# STM32H7RSxx register map
File version: 0.1
CPU: CM7 r0p1, little endian, MPU, FPU, 4 interrupt priority bits
Registers are 32-bit, read-write, reset 0x0 unless marked. A register's access mark holds for its fields unless they carry their own. Offsets are from the block's base; [hi:lo] are bit positions; lines under a group give offsets from that group; {n}, {i} and the like mark numbered series.

## ADC1 (part 1 of 2) — Analog to digital converter
Base 0x40022000
Same registers: ADC2 0x40022100
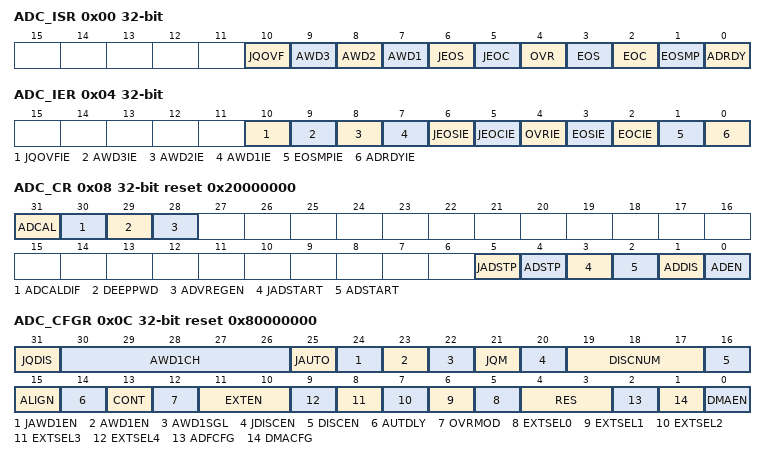
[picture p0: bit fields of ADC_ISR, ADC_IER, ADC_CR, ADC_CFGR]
0x00 ADC_ISR — ADC interrupt and status register
  [10] JQOVF — Injected context queue overflow This bit is set by hardware when an Overflow of the Injected Queue of Context occurs. It is cleared by software writing 1 to it. Refer to for more information.
    0=No injected context queue overflow occurred (or the flag event was already acknowledged and cleared by software); 1=Injected context queue overflow has occurred
  [9] AWD3 — Analog watchdog 3 flag This bit is set by hardware when the converted voltage crosses the values programmed in the fields LT3[7:0] and HT3[7:0] of ADC_TR3 register. It is cleared by software writing 1 to it.
    0=No analog watchdog 3 event occurred (or the flag event was already acknowledged and cleared by software); 1=Analog watchdog 3 event occurred
  [8] AWD2 — Analog watchdog 2 flag This bit is set by hardware when the converted voltage crosses the values programmed in the fields LT2[7:0] and HT2[7:0] of ADC_TR2 register. It is cleared by software writing 1 to it.
    0=No analog watchdog 2 event occurred (or the flag event was already acknowledged and cleared by software); 1=Analog watchdog 2 event occurred
  [7] AWD1 — Analog watchdog 1 flag This bit is set by hardware when the converted voltage crosses the values programmed in the fields LT1[11:0] and HT1[11:0] of ADC_TR1 register. It is cleared by software. writing 1 to it.
    0=No analog watchdog 1 event occurred (or the flag event was already acknowledged and cleared by software); 1=Analog watchdog 1 event occurred
  [6] JEOS — Injected channel end of sequence flag This bit is set by hardware at the end of the conversions of all injected channels in the group. It is cleared by software writing 1 to it.
    0=Injected conversion sequence not complete (or the flag event was already acknowledged and cleared by software); 1=Injected conversions complete
  [5] JEOC — Injected channel end of conversion flag This bit is set by hardware at the end of each injected conversion of a channel when a new data is available in the corresponding ADC_JDRy register. It is cleared by software writing 1 to it or by reading the corresponding ADC_JDRy register
    0=Injected channel conversion not complete (or the flag event was already acknowledged and cleared by software); 1=Injected channel conversion complete
  [4] OVR — ADC overrun This bit is set by hardware when an overrun occurs on a regular channel, meaning that a new conversion has completed while the EOC flag was already set. It is cleared by software writing 1 to it.
    0=No overrun occurred (or the flag event was already acknowledged and cleared by software); 1=Overrun has occurred
  [3] EOS — End of regular sequence flag This bit is set by hardware at the end of the conversions of a regular sequence of channels. It is cleared by software writing 1 to it.
    0=Regular Conversions sequence not complete (or the flag event was already acknowledged and cleared by software); 1=Regular Conversions sequence complete
  [2] EOC — End of conversion flag This bit is set by hardware at the end of each regular conversion of a channel when a new data is available in the ADC_DR register. It is cleared by software writing 1 to it or by reading the ADC_DR register
    0=Regular channel conversion not complete (or the flag event was already acknowledged and cleared by software); 1=Regular channel conversion complete
  [1] EOSMP — End of sampling flag This bit is set by hardware during the conversion of any channel (only for regular channels), at the end of the sampling phase.
    0=not at the end of the sampling phase (or the flag event was already acknowledged and cleared by software); 1=End of sampling phase reached
  [0] ADRDY — ADC ready This bit is set by hardware after the ADC has been enabled (ADEN = 1) and when the ADC reaches a state where it is ready to accept conversion requests. It is cleared by software writing 1 to it.
    0=ADC not yet ready to start conversion (or the flag event was already acknowledged and cleared by software); 1=ADC is ready to start conversion
0x04 ADC_IER — ADC interrupt enable register
  [10] JQOVFIE — Injected context queue overflow interrupt enable This bit is set and cleared by software to enable/disable the Injected Context Queue Overflow interrupt. Note: The software is allowed to write this bit only when JADSTART = 0 (which ensures that no injected conversion is ongoing).
    0=Injected Context Queue Overflow interrupt disabled; 1=Injected Context Queue Overflow interrupt enabled. An interrupt is generated when the JQOVF bit is set.
  [9] AWD3IE — Analog watchdog 3 interrupt enable This bit is set and cleared by software to enable/disable the analog watchdog 2 interrupt. Note: The software is allowed to write this bit only when ADSTART = 0 and JADSTART = 0 (which ensures that no conversion is ongoing).
    0=Analog watchdog 3 interrupt disabled; 1=Analog watchdog 3 interrupt enabled
  [8] AWD2IE — Analog watchdog 2 interrupt enable This bit is set and cleared by software to enable/disable the analog watchdog 2 interrupt. Note: The software is allowed to write this bit only when ADSTART = 0 and JADSTART = 0 (which ensures that no conversion is ongoing).
    0=Analog watchdog 2 interrupt disabled; 1=Analog watchdog 2 interrupt enabled
  [7] AWD1IE — Analog watchdog 1 interrupt enable This bit is set and cleared by software to enable/disable the analog watchdog 1 interrupt. Note: The software is allowed to write this bit only when ADSTART = 0 and JADSTART = 0 (which ensures that no conversion is ongoing).
    0=Analog watchdog 1 interrupt disabled; 1=Analog watchdog 1 interrupt enabled
  [6] JEOSIE — End of injected sequence of conversions interrupt enable This bit is set and cleared by software to enable/disable the end of injected sequence of conversions interrupt. Note: The software is allowed to write this bit only when JADSTART = 0 (which ensures that no injected conversion is ongoing).
    0=JEOS interrupt disabled; 1=JEOS interrupt enabled. An interrupt is generated when the JEOS bit is set.
  [5] JEOCIE — End of injected conversion interrupt enable This bit is set and cleared by software to enable/disable the end of an injected conversion interrupt. Note: The software is allowed to write this bit only when JADSTART = 0 (which ensures that no injected conversion is ongoing).
    0=JEOC interrupt disabled; 1=JEOC interrupt enabled. An interrupt is generated when the JEOC bit is set.
  [4] OVRIE — Overrun interrupt enable This bit is set and cleared by software to enable/disable the Overrun interrupt of a regular conversion. Note: The software is allowed to write this bit only when ADSTART = 0 (which ensures that no regular conversion is ongoing).
    0=Overrun interrupt disabled; 1=Overrun interrupt enabled. An interrupt is generated when the OVR bit is set.
  [3] EOSIE — End of regular sequence of conversions interrupt enable This bit is set and cleared by software to enable/disable the end of regular sequence of conversions interrupt. Note: The software is allowed to write this bit only when ADSTART = 0 (which ensures that no regular conversion is ongoing).
    0=EOS interrupt disabled; 1=EOS interrupt enabled. An interrupt is generated when the EOS bit is set.
  [2] EOCIE — End of regular conversion interrupt enable This bit is set and cleared by software to enable/disable the end of a regular conversion interrupt. Note: The software is allowed to write this bit only when ADSTART = 0 (which ensures that no regular conversion is ongoing).
    0=EOC interrupt disabled; 1=EOC interrupt enabled. An interrupt is generated when the EOC bit is set.
  [1] EOSMPIE — End of sampling flag interrupt enable for regular conversions This bit is set and cleared by software to enable/disable the end of the sampling phase interrupt for regular conversions. Note: The software is allowed to write this bit only when ADSTART = 0 (which ensures that no regular conversion is ongoing).
    0=EOSMP interrupt disabled; 1=EOSMP interrupt enabled. An interrupt is generated when the EOSMP bit is set.
  [0] ADRDYIE — ADC ready interrupt enable This bit is set and cleared by software to enable/disable the ADC Ready interrupt. Note: The software is allowed to write this bit only when ADSTART = 0 and JADSTART = 0 (which ensures that no conversion is ongoing).
    0=ADRDY interrupt disabled; 1=ADRDY interrupt enabled. An interrupt is generated when the ADRDY bit is set.
0x08 ADC_CR reset 0x20000000 — ADC control register
  [31] ADCAL — ADC calibration This bit is set by software to start the calibration of the ADC. Program first the bit ADCALDIF to determine if this calibration applies for Single-ended or Differential inputs mode. It is cleared by hardware after calibration is complete. Note: The software is allowed to launch a calibration by setting ADCAL only when ADEN = 0. The software is allowed to update the calibration factor by writing ADC_CALFACT only when ADEN = 1 and ADSTART = 0 and JADSTART = 0 (ADC enabled and no conversion is ongoing)
    0=Calibration complete; 1=Write 1 to calibrate the ADC. Read at 1 means that a calibration in progress.
  [30] ADCALDIF — Differential mode for calibration This bit is set and cleared by software to configure the Single-ended or Differential inputs mode for the calibration. Note: The software is allowed to write this bit only when the ADC is disabled and is not calibrating (ADCAL = 0, JADSTART = 0, JADSTP = 0, ADSTART = 0, ADSTP = 0, ADDIS = 0 and ADEN = 0).
    0=Writing ADCAL launches a calibration in Single-ended inputs mode; 1=Writing ADCAL launches a calibration in Differential inputs mode
  [29] DEEPPWD — Deep-power-down enable This bit is set and cleared by software to put the ADC in Deep-power-down mode. Note: The software is allowed to write this bit only when the ADC is disabled (ADCAL = 0, JADSTART = 0, JADSTP = 0, ADSTART = 0, ADSTP = 0, ADDIS = 0 and ADEN = 0).
    0=ADC not in Deep-power down; 1=ADC in Deep-power-down (default reset state)
  [28] ADVREGEN — ADC voltage regulator enable This bits is set by software to enable the ADC voltage regulator. Before performing any operation such as launching a calibration or enabling the ADC, the ADC voltage regulator must first be enabled and the software must wait for the regulator start-up time. For more details about the ADC voltage regulator enable and disable sequences, refer to (ADVREGEN). The software can program this bit field only when the ADC is disabled (ADCAL = 0, JADSTART = 0, ADSTART = 0, ADSTP = 0, ADDIS = 0 and ADEN = 0).
    0=ADC Voltage regulator disabled; 1=ADC Voltage regulator enabled
  [5] JADSTP — ADC stop of injected conversion command This bit is set by software to stop and discard an ongoing injected conversion (JADSTP Command). It is cleared by hardware when the conversion is effectively discarded and the ADC injected sequence and triggers can be re-configured. The ADC is then ready to accept a new start of injected conversions (JADSTART command). Note: The software is allowed to set JADSTP only when JADSTART = 1 and ADDIS = 0 (ADC is enabled and eventually converting an injected conversion and there is no pending request to disable the ADC) In Auto-injection mode (JAUTO = 1), setting ADSTP bit aborts both regular and injected conversions (do not use JADSTP)
    0=No ADC stop injected conversion command ongoing; 1=Write 1 to stop injected conversions ongoing. Read 1 means that an ADSTP command is in progress.
  [4] ADSTP — ADC stop of regular conversion command This bit is set by software to stop and discard an ongoing regular conversion (ADSTP Command). It is cleared by hardware when the conversion is effectively discarded and the ADC regular sequence and triggers can be re-configured. The ADC is then ready to accept a new start of regular conversions (ADSTART command). Note: The software is allowed to set ADSTP only when ADSTART = 1 and ADDIS = 0 (ADC is enabled and eventually converting a regular conversion and there is no pending request to disable the ADC). In auto-injection mode (JAUTO = 1), setting ADSTP bit aborts both regular and injected conversions (do not use JADSTP).
    0=No ADC stop regular conversion command ongoing; 1=Write 1 to stop regular conversions ongoing. Read 1 means that an ADSTP command is in progress.
  [3] JADSTART — ADC start of injected conversion This bit is set by software to start ADC conversion of injected channels. Depending on the configuration bits JEXTEN, a conversion immediately starts (software trigger configuration) or once an injected hardware trigger event occurs (hardware trigger configuration). It is cleared by hardware: in Single conversion mode when software trigger is selected (JEXTSEL = 0x0): at the assertion of the End of Injected Conversion Sequence (JEOS) flag. in all cases: after the execution of the JADSTP command, at the same time that JADSTP is cleared by hardware. Note: The software is allowed to set JADSTART only when ADEN = 1 and ADDIS = 0 (ADC is enabled and there is no pending request to disable the ADC). In auto-injection mode (JAUTO = 1), regular and auto-injected conversions are started by setting bit ADSTART (JADSTART must be kept cleared)
    0=No ADC injected conversion is ongoing; 1=Write 1 to start injected conversions. Read 1 means that the ADC is operating and eventually converting an injected channel.
  [2] ADSTART — ADC start of regular conversion This bit is set by software to start ADC conversion of regular channels. Depending on the configuration bits EXTEN, a conversion immediately starts (software trigger configuration) or once a regular hardware trigger event occurs (hardware trigger configuration). It is cleared by hardware: in Single conversion mode when software trigger is selected (EXTSEL = 0x0): at the assertion of the End of Regular Conversion Sequence (EOS) flag. in all cases: after the execution of the ADSTP command, at the same time that ADSTP is cleared by hardware. Note: The software is allowed to set ADSTART only when ADEN = 1 and ADDIS = 0 (ADC is enabled and there is no pending request to disable the ADC) In auto-injection mode (JAUTO = 1), regular and auto-injected conversions are started by setting bit ADSTART (JADSTART must be kept cleared)
    0=No ADC regular conversion is ongoing; 1=Write 1 to start regular conversions. Read 1 means that the ADC is operating and eventually converting a regular channel.
  [1] ADDIS — ADC disable command This bit is set by software to disable the ADC (ADDIS command) and put it into power-down state (OFF state). It is cleared by hardware once the ADC is effectively disabled (ADEN is also cleared by hardware at this time). Note: The software is allowed to set ADDIS only when ADEN = 1 and both ADSTART = 0 and JADSTART = 0 (which ensures that no conversion is ongoing)
    0=no ADDIS command ongoing; 1=Write 1 to disable the ADC. Read 1 means that an ADDIS command is in progress.
  [0] ADEN — ADC enable control This bit is set by software to enable the ADC. The ADC is effectively ready to operate once the flag ADRDY has been set. It is cleared by hardware when the ADC is disabled, after the execution of the ADDIS command. Note: The software is allowed to set ADEN only when all bits of ADC_CR registers are 0 (ADCAL = 0, JADSTART = 0, ADSTART = 0, ADSTP = 0, ADDIS = 0 and ADEN = 0) except for bit ADVREGEN which must be 1 (and the software must have wait for the startup time of the voltage regulator)
    0=ADC is disabled (OFF state); 1=Write 1 to enable the ADC
0x0C ADC_CFGR reset 0x80000000 — ADC configuration register
  [31] JQDIS — Injected Queue disable These bits are set and cleared by software to disable the Injected Queue mechanism : Note: The software is allowed to write this bit only when ADSTART = 0 and JADSTART = 0 (which ensures that no regular nor injected conversion is ongoing). A set or reset of JQDIS bit causes the injected queue to be flushed and the JSQR register is cleared.
    0=Injected Queue enabled; 1=Injected Queue disabled
  [30:26] AWD1CH — Analog watchdog 1 channel selection These bits are set and cleared by software. They select the input channel to be guarded by the analog watchdog. ..... others: reserved, must not be used Note: Some channels are not connected physically. Keep the corresponding AWD1CH[4:0] setting to the reset value. The channel selected by AWD1CH must be also selected into the SQRi or JSQRi registers. The software is allowed to write these bits only when ADSTART = 0 and JADSTART = 0 (which ensures that no conversion is ongoing).
    0=ADC analog input channel 0 monitored by AWD1 (available on ADC1 only); 1=ADC analog input channel 1 monitored by AWD1; 19=ADC analog input channel 19 monitored by AWD1
  [25] JAUTO — Automatic injected group conversion This bit is set and cleared by software to enable/disable automatic injected group conversion after regular group conversion. Note: The software is allowed to write this bit only when ADSTART = 0 and JADSTART = 0 (which ensures that no regular nor injected conversion is ongoing). When dual mode is enabled (DUAL bits in ADC_CCR register are not equal to zero), the bit JAUTO of the slave ADC is no more writable and its content is equal to the bit JAUTO of the master ADC.
    0=Automatic injected group conversion disabled; 1=Automatic injected group conversion enabled
  [24] JAWD1EN — Analog watchdog 1 enable on injected channels This bit is set and cleared by software Note: The software is allowed to write this bit only when JADSTART = 0 (which ensures that no injected conversion is ongoing).
    0=Analog watchdog 1 disabled on injected channels; 1=Analog watchdog 1 enabled on injected channels
  [23] AWD1EN — Analog watchdog 1 enable on regular channels This bit is set and cleared by software Note: The software is allowed to write this bit only when ADSTART = 0 (which ensures that no regular conversion is ongoing).
    0=Analog watchdog 1 disabled on regular channels; 1=Analog watchdog 1 enabled on regular channels
  [22] AWD1SGL — Enable the watchdog 1 on a single channel or on all channels This bit is set and cleared by software to enable the analog watchdog on the channel identified by the AWD1CH[4:0] bits or on all the channels Note: The software is allowed to write these bits only when ADSTART = 0 and JADSTART = 0 (which ensures that no conversion is ongoing).
    0=Analog watchdog 1 enabled on all channels; 1=Analog watchdog 1 enabled on a single channel
  [21] JQM — JSQR queue mode This bit is set and cleared by software. It defines how an empty Queue is managed. Refer to for more information. Note: The software is allowed to write this bit only when JADSTART = 0 (which ensures that no injected conversion is ongoing). When dual mode is enabled (DUAL bits in ADC_CCR register are not equal to zero), the bit JQM of the slave ADC is no more writable and its content is equal to the bit JQM of the master ADC.
    0=JSQR mode 0: The Queue is never empty and maintains the last written configuration into JSQR; 1=JSQR mode 1: The Queue can be empty and when this occurs, the software and hardware triggers of the injected sequence are both internally disabled just after the completion of the last valid injected sequence
  [20] JDISCEN — Discontinuous mode on injected channels This bit is set and cleared by software to enable/disable Discontinuous mode on the injected channels of a group. Note: The software is allowed to write this bit only when JADSTART = 0 (which ensures that no injected conversion is ongoing). It is not possible to use both auto-injected mode and Discontinuous mode simultaneously: the bits DISCEN and JDISCEN must be kept cleared by software when JAUTO is set. When dual mode is enabled (bits DUAL of ADC_CCR register are not equal to zero), the bit JDISCEN of the slave ADC is no more writable and its content is equal to the bit JDISCEN of the master ADC.
    0=Discontinuous mode on injected channels disabled; 1=Discontinuous mode on injected channels enabled
  [19:17] DISCNUM — Discontinuous mode channel count These bits are written by software to define the number of regular channels to be converted in Discontinuous mode, after receiving an external trigger. ... Note: The software is allowed to write these bits only when ADSTART = 0 (which ensures that no regular conversion is ongoing). When dual mode is enabled (DUAL bits in ADC_CCR register are not equal to zero), the bits DISCNUM[2:0] of the slave ADC are no more writable and their content is equal to the bits DISCNUM[2:0] of the master ADC.
    0=1 channel; 1=2 channels; 7=8 channels
  [16] DISCEN — Discontinuous mode for regular channels This bit is set and cleared by software to enable/disable Discontinuous mode for regular channels. Note: It is not possible to have both Discontinuous mode and Continuous mode enabled: it is forbidden to set both DISCEN = 1 and CONT = 1. It is not possible to use both auto-injected mode and Discontinuous mode simultaneously: the bits DISCEN and JDISCEN must be kept cleared by software when JAUTO is set. The software is allowed to write this bit only when ADSTART = 0 (which ensures that no regular conversion is ongoing). When dual mode is enabled (DUAL bits in ADC_CCR register are not equal to zero), the bit DISCEN of the slave ADC is no more writable and its content is equal to the bit DISCEN of the master ADC.
    0=Discontinuous mode for regular channels disabled; 1=Discontinuous mode for regular channels enabled
  [15] ALIGN — Data alignment This bit is set and cleared by software to select right or left alignment. Refer to register, data alignment and offset (ADC_DR, OFFSET, OFFSET_CH, ALIGN). Note: The software is allowed to write this bit only when ADSTART = 0 and JADSTART = 0 (which ensures that no conversion is ongoing).
    0=Right alignment; 1=Left alignment
  [14] AUTDLY — Delayed conversion mode This bit is set and cleared by software to enable/disable the Auto Delayed Conversion mode.. Note: The software is allowed to write this bit only when ADSTART = 0 and JADSTART = 0 (which ensures that no conversion is ongoing). When dual mode is enabled (DUAL bits in ADC_CCR register are not equal to zero), the bit AUTDLY of the slave ADC is no more writable and its content is equal to the bit AUTDLY of the master ADC.
    0=Auto-delayed conversion mode off; 1=Auto-delayed conversion mode on
  [13] CONT — Single / Continuous conversion mode for regular conversions This bit is set and cleared by software. If it is set, regular conversion takes place continuously until it is cleared. Note: It is not possible to have both Discontinuous mode and Continuous mode enabled: it is forbidden to set both DISCEN = 1 and CONT = 1. The software is allowed to write this bit only when ADSTART = 0 (which ensures that no regular conversion is ongoing). When dual mode is enabled (DUAL bits in ADC_CCR register are not equal to zero), the bit CONT of the slave ADC is no more writable and its content is equal to the bit CONT of the master ADC.
    0=Single conversion mode; 1=Continuous conversion mode
  [12] OVRMOD — Overrun mode This bit is set and cleared by software and configure the way data overrun is managed. Note: The software is allowed to write this bit only when ADSTART = 0 (which ensures that no regular conversion is ongoing).
    0=ADC_DR register is preserved with the old data when an overrun is detected; 1=ADC_DR register is overwritten with the last conversion result when an overrun is detected
  [11:10] EXTEN — External trigger enable and polarity selection for regular channels These bits are set and cleared by software to select the external trigger polarity and enable the trigger of a regular group. Note: The software is allowed to write these bits only when ADSTART = 0 (which ensures that no regular conversion is ongoing).
    0=Hardware trigger detection disabled (conversions can be launched by software); 1=Hardware trigger detection on the rising edge; 2=Hardware trigger detection on the falling edge; 3=Hardware trigger detection on both the rising and falling edges
  [n+5] EXTSEL{n} (n=0..4) — External trigger selection for regular group These bits select the external event used to trigger the start of conversion of a regular group: ... Note: The software is allowed to write these bits only when ADSTART = 0 (which ensures that no regular conversion is ongoing).
    {v}=adc_ext_trg{v} (v=0..7); 31=adc_ext_trg31
  [4:3] RES — Data resolution These bits are written by software to select the resolution of the conversion. Note: The software is allowed to write these bits only when ADSTART = 0 and JADSTART = 0 (which ensures that no conversion is ongoing).
    0=12-bit; 1=10-bit; 2=8-bit; 3=6-bit
  [2] ADFCFG — ADF mode configuration This bit is set and cleared by software to enable the ADF mode. It is effective only when DMAEN = 0.
    0=ADF mode disabled; 1=ADF mode enabled
  [1] DMACFG — Direct memory access configuration This bit is set and cleared by software to select between two DMA modes of operation and is effective only when DMAEN = 1. For more details, refer to Note: The software is allowed to write this bit only when ADSTART = 0 and JADSTART = 0 (which ensures that no conversion is ongoing). In dual-ADC modes, this bit is not relevant and replaced by control bit DMACFG of the ADC_CCR register.
    0=DMA One Shot mode selected; 1=DMA Circular mode selected
  [0] DMAEN — Direct memory access enable This bit is set and cleared by software to enable the generation of DMA requests. This allows to use the DMA to manage automatically the converted data. For more details, refer to conversions using the DMA. Note: The software is allowed to write this bit only when ADSTART = 0 and JADSTART = 0 (which ensures that no conversion is ongoing). In dual-ADC modes, this bit is not relevant and replaced by control bits MDMA[1:0] of the ADC_CCR register.
    0=DMA disabled; 1=DMA enabled
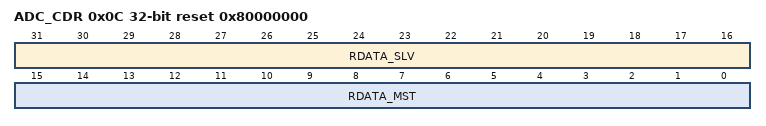
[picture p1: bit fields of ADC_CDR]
0x0C ADC_CDR ro reset 0x80000000 (alternate view of ADC_CFGR) — ADC_CDR_mode
  [31:16] RDATA_SLV — Regular data of the slave ADC In dual mode, these bits contain the regular data of the slave ADC. Refer to Dual ADC modes. The data alignment is applied as described in offset (ADC_DR, OFFSET, OFFSET_CH, ALIGN))
  [15:0] RDATA_MST — Regular data of the master ADC. In dual mode, these bits contain the regular data of the master ADC. Refer to . The data alignment is applied as described in offset (ADC_DR, OFFSET, OFFSET_CH, ALIGN)) In MDMA = 0b11 mode, bits 15:8 contains SLV_ADC_DR[7:0], bits 7:0 contains MST_ADC_DR[7:0].
